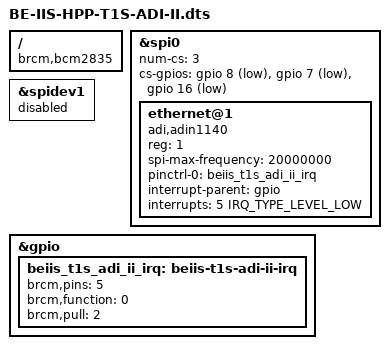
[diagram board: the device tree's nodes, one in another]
// SPDX-License-Identifier: GPL-2.0-or-later
// BE-IIS-HPP-T1S-ADI, HAT++ instance II
// SPI0 CE1: BCM GPIO7; IRQ/BUSY: BCM GPIO5
// 10BASE-T1S MAC-PHY.
// Requires SPI0 enabled. GPIO numbers are BCM, not physical header pin numbers.
/dts-v1/;
/plugin/;

#include <dt-bindings/interrupt-controller/irq.h>
#include <dt-bindings/gpio/gpio.h>

/ {
    compatible = "brcm,bcm2835", "brcm,bcm2711", "brcm,bcm2712";

    fragment@0 {
        target = <&spi0>;
        __overlay__ {
            #address-cells = <1>;
            #size-cells = <0>;
            status = "okay";
            num-cs = <3>;
            cs-gpios = <&gpio 8 GPIO_ACTIVE_LOW>,
                       <&gpio 7 GPIO_ACTIVE_LOW>,
                       <&gpio 16 GPIO_ACTIVE_LOW>;

            ethernet@1 {
                compatible = "adi,adin1140", "adi,ad3306";
                reg = <1>;
                spi-max-frequency = <20000000>;
                pinctrl-names = "default";
                pinctrl-0 = <&beiis_t1s_adi_ii_irq>;
                interrupt-parent = <&gpio>;
                interrupts = <5 IRQ_TYPE_LEVEL_LOW>;
                status = "okay";
            };
        };
    };

    fragment@1 {
        target = <&spidev1>;
        __overlay__ { status = "disabled"; };
    };
    fragment@2 {
        target = <&gpio>;
        __overlay__ {
            beiis_t1s_adi_ii_irq: beiis-t1s-adi-ii-irq {
                brcm,pins = <5>;
                brcm,function = <0>; /* input */
                brcm,pull = <2>; /* pull-up */
            };
        };
    };
};
